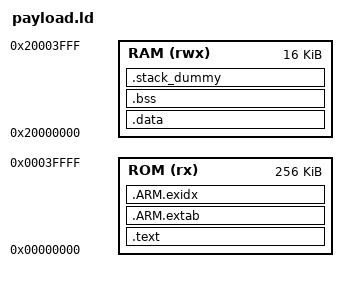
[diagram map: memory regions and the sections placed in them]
OUTPUT_FORMAT("elf32-littlearm", "elf32-bigarm", "elf32-littlearm")
OUTPUT_ARCH(arm)

/* 256KB Flash, 16KB RAM */
MEMORY
{
  ROM (rx) : ORIGIN = 0x00000000, LENGTH = 0x40000
  RAM (rwx) :  ORIGIN = 0x20000000, LENGTH = 0x4000
}

SECTIONS
{
  .text :
  {
    KEEP(*(.vectors))
    *(.text*)
    *(.rodata*)
  } > ROM

  .ARM.extab : 
  {
    *(.ARM.extab* .gnu.linkonce.armextab.*)
  } > ROM

  .ARM.exidx :
  {
    *(.ARM.exidx* .gnu.linkonce.armexidx.*)
  } > ROM

  __etext = .;
  .data : AT (__etext)
  {
    . = ALIGN(4);
    __data_start = .;
    *(.data*)
    . = ALIGN(4);
    __data_end = .;
  } > RAM

  .bss :
  {
    . = ALIGN(4);
    __bss_start = .;
    *(.bss*)
    *(COMMON)
    . = ALIGN(4);
    __bss_end = .;
  } > RAM
	
  .stack_dummy (COPY):
  {
    *(.stack*)
  } > RAM

  /* Set stack top to end of RAM, and stack limit move down by
   * size of stack_dummy section */
  __stack_top = ORIGIN(RAM) + LENGTH(RAM);
  PROVIDE(__stack = __stack_top);
}

